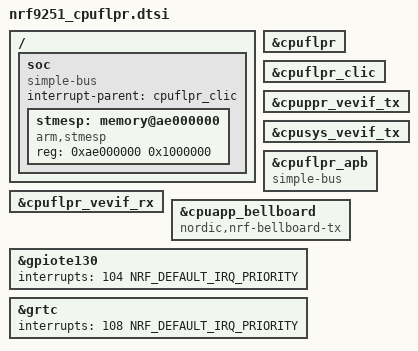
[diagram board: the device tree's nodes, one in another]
/*
 * Copyright (c) 2026 Nordic Semiconductor ASA
 *
 * SPDX-License-Identifier: LicenseRef-Nordic-5-Clause
 */

#include <nordic/nrf9251.dtsi>

cpu: &cpuflpr {};

clic: &cpuflpr_clic {};

cpuppr_vevif: &cpuppr_vevif_tx {};

cpuflpr_vevif: &cpuflpr_vevif_rx {};

cpusys_vevif: &cpusys_vevif_tx {};

/delete-node/ &cpuapp;
/delete-node/ &cpuapp_peripherals;
/delete-node/ &cpuapp_ppb;
/delete-node/ &cpuapp_ram0x_sram;
/delete-node/ &cpuppr;

/ {
	soc {
		compatible = "simple-bus";
		interrupt-parent = <&cpuflpr_clic>;
		ranges;

		stmesp: memory@ae000000 {
			compatible = "arm,stmesp";
			reg = <0xae000000 0x1000000>;
		};
	};
};

&cpuflpr_apb {
	compatible = "simple-bus";
	ranges;
};

&cpuflpr_clic {
	status = "okay";
};

&cpuapp_bellboard {
	compatible = "nordic,nrf-bellboard-tx";
};

&gpiote130 {
	interrupts = <104 NRF_DEFAULT_IRQ_PRIORITY>;
};

&grtc {
	interrupts = <108 NRF_DEFAULT_IRQ_PRIORITY>;
};
